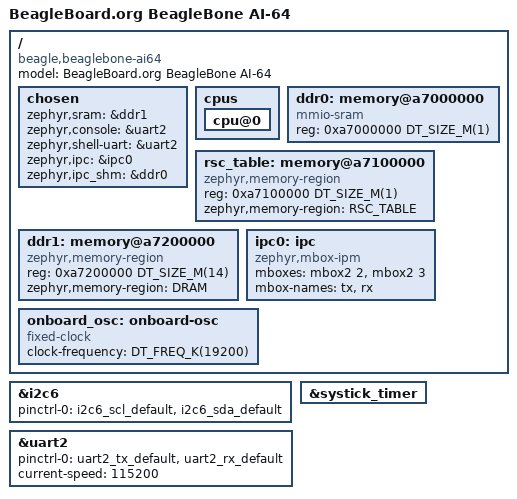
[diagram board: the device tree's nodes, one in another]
/dts-v1/;

#include <ti/j721e_main_r5.dtsi>
#include "beaglebone_ai64_j721e_main_r5f1_1-pinctrl.dtsi"
#include <freq.h>

/ {
	model = "BeagleBoard.org BeagleBone AI-64";
	compatible = "beagle,beaglebone-ai64";

	chosen {
		zephyr,sram = &ddr1;
		zephyr,console = &uart2;
		zephyr,shell-uart = &uart2;
		zephyr,ipc = &ipc0;
		zephyr,ipc_shm = &ddr0;
	};

	cpus {
		cpu@0 {
			status = "okay";
		};
	};

	ddr0: memory@a7000000 {
		compatible = "mmio-sram";
		reg = <0xa7000000 DT_SIZE_M(1)>;
	};

	rsc_table: memory@a7100000 {
		compatible = "zephyr,memory-region", "mmio-sram";
		reg = <0xa7100000 DT_SIZE_M(1)>;
		zephyr,memory-region = "RSC_TABLE";
	};

	ddr1: memory@a7200000 {
		compatible = "zephyr,memory-region", "mmio-sram";
		reg = <0xa7200000 DT_SIZE_M(14)>;
		zephyr,memory-region = "DRAM";
	};

	ipc0: ipc {
		compatible = "zephyr,mbox-ipm";
		mboxes = <&mbox2 2>, <&mbox2 3>;
		mbox-names = "tx", "rx";
	};

	onboard_osc: onboard-osc {
		compatible = "fixed-clock";
		clock-frequency = <DT_FREQ_K(19200)>;
		#clock-cells = <0>;
	};
};

&i2c6 {
	status = "okay";
	pinctrl-0 = <&i2c6_scl_default &i2c6_sda_default>;
	pinctrl-names = "default";
};

&uart2 {
	status = "okay";
	pinctrl-0 = <&uart2_tx_default &uart2_rx_default>;
	pinctrl-names = "default";
	current-speed = <115200>;
};

&systick_timer {
	status = "okay";
};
